# cpu_riscv_chisel_book register map
Vendor: fugafuga.org; Series: cpu_riscv_chisel_book; File version: 0.1
RISC-V Chisel Book CPU peripherals
Registers are 32-bit, read-write, reset 0x0 unless marked. A register's access mark holds for its fields unless they carry their own. Offsets are from the block's base; lines under a group give offsets from that group; [hi:lo] are bit positions; {n}, {i} and the like mark numbered series; 'fields as' and 'values as' point back to an identical list; <NAME> marks a mode.

## Memory map
0xA0000000 GPIO
0xB0000000 UART — Simple UART

## GPIO
Base 0xA0000000
0x00 DATA
  [5:0] LED range 0x00..0x3f

## UART — Simple UART
Base 0xB0000000
0x00 TXD
  [7:0] DATA wo range 0x00..0xff
0x00 RXD
  [7:0] RXD ro
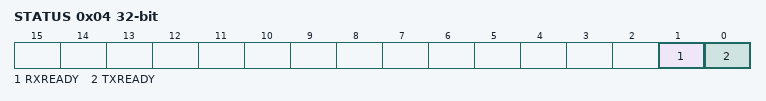
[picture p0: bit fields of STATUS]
0x04 STATUS
  [1] RXREADY
    1=ready; 0=notready
  [0] TXREADY
    1=ready; 0=notready
